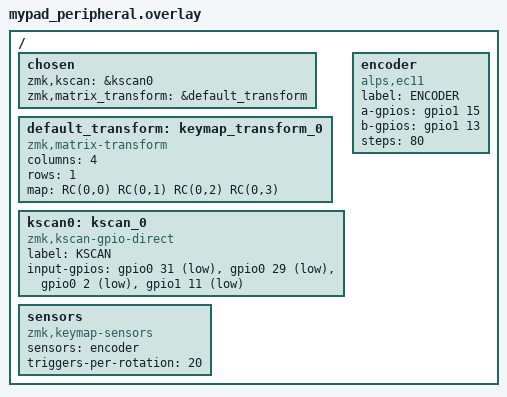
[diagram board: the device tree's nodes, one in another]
#include <dt-bindings/zmk/matrix_transform.h>

/ {
    chosen {
        zmk,kscan = &kscan0;
        zmk,matrix_transform = &default_transform;
    };

    default_transform: keymap_transform_0 {
        compatible = "zmk,matrix-transform";
        columns = <4>;
        rows = <1>;
        map = <
            RC(0,0) RC(0,1) RC(0,2) RC(0,3)
        >;
    };

    kscan0: kscan_0 {
        compatible = "zmk,kscan-gpio-direct";
        label = "KSCAN";
        input-gpios
            = <&gpio0 31 (GPIO_ACTIVE_LOW | GPIO_PULL_UP)>
            , <&gpio0 29 (GPIO_ACTIVE_LOW | GPIO_PULL_UP)>
            , <&gpio0 2 (GPIO_ACTIVE_LOW | GPIO_PULL_UP)>
            , <&gpio1 11 (GPIO_ACTIVE_LOW | GPIO_PULL_UP)>
            ;
    };

    encoder: encoder {
        compatible = "alps,ec11";
        label = "ENCODER";
        a-gpios = <&gpio1 15 (GPIO_ACTIVE_HIGH | GPIO_PULL_UP)>;
        b-gpios = <&gpio1 13 (GPIO_ACTIVE_HIGH | GPIO_PULL_UP)>;
        steps = <80>;
        status = "okay";
    };

    sensors: sensors {
        compatible = "zmk,keymap-sensors";
        sensors = <&encoder>;
        triggers-per-rotation = <20>;
    };
};
